# STM32H7B3x register map
File version: 2.2
CPU: CM7 r0p1, little endian, MPU, FPU, 4 interrupt priority bits
Registers are 32-bit, read-write, reset 0x0 unless marked. A register's access mark holds for its fields unless they carry their own. Offsets are from the block's base; [hi:lo] are bit positions.

## RNG
Base 0x48021800
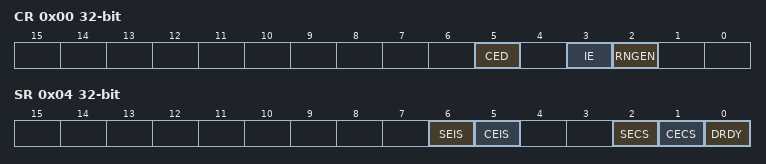
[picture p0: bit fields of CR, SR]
0x00 CR — RNG control register
  [5] CED — Clock error detection Note: The clock error detection can be used only when ck_rc48 or ck_pll1_q (ck_pll1_q = 48MHz) source is selected otherwise, CED bit must be equal to 1. The clock error detection cannot be enabled nor disabled on the fly when RNG peripheral is enabled, to enable or disable CED the RNG must be disabled.
    0=Enabled (Clock error detection is enabled); 1=Disabled (Clock error detection is disabled)
  [3] IE — Interrupt enable
    0=Disabled (RNG interrupt is disabled); 1=Enabled (RNG interrupt is enabled)
  [2] RNGEN — Random number generator enable
    0=Disabled (Random number generator is disabled); 1=Enabled (Random number generator is enabled)
0x04 SR access per field — RNG status register
  [6] SEIS rw — Seed error interrupt status This bit is set at the same time as SECS. It is cleared by writing it to 0. ** More than 64 consecutive bits at the same value (0 or 1) ** More than 32 consecutive alternances of 0 and 1 (0101010101...01) An interrupt is pending if IE = 1 in the RNG_CR register.
  [5] CEIS rw — Clock error interrupt status This bit is set at the same time as CECS. It is cleared by writing it to 0. An interrupt is pending if IE = 1 in the RNG_CR register. Note: This bit is meaningless if CED (Clock error detection) bit in RNG_CR is equal to 1.
  [2] SECS ro — Seed error current status ** More than 64 consecutive bits at the same value (0 or 1) ** More than 32 consecutive alternances of 0 and 1 (0101010101...01)
  [1] CECS ro — Clock error current status Note: This bit is meaningless if CED (Clock error detection) bit in RNG_CR is equal to 1.
  [0] DRDY ro — Data ready Note: If IE=1 in RNG_CR, an interrupt is generated when DRDY=1. It can rise when the peripheral is disabled. When the output buffer becomes empty (after reading RNG_DR), this bit returns to 0 until a new random value is generated.
0x08 DR ro — The RNG_DR register is a read-only register that delivers a 32-bit random value when read. The content of this register is valid when DRDY= 1, even if RNGEN=0.
  [31:0] RNDATA — Random data 32-bit random data which are valid when DRDY=1.

## SCB_ACTRL — System control block ACTLR
Base 0xE000E008
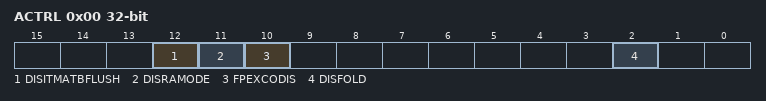
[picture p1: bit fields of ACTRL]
0x00 ACTRL — Auxiliary control register
  [12] DISITMATBFLUSH, [11] DISRAMODE, [10] FPEXCODIS, [2] DISFOLD

## SPDIFRX — Receiver Interface
Base 0x40004000
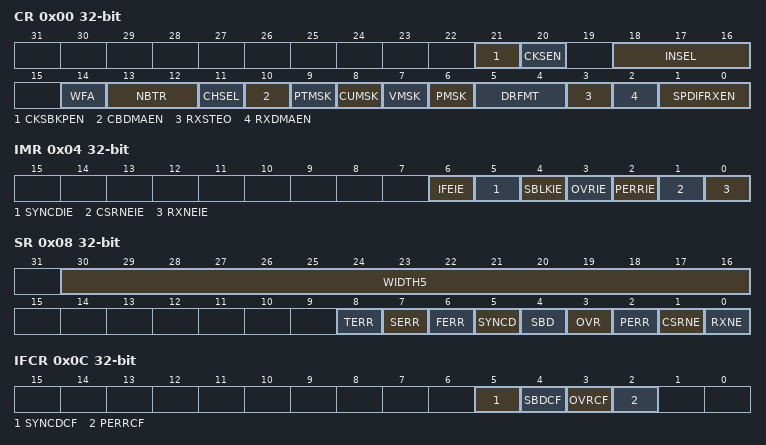
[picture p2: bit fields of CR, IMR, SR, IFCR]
0x00 CR — Control register
  [21] CKSBKPEN — Backup Symbol Clock Enable
  [20] CKSEN — Symbol Clock Enable
  [18:16] INSEL — input selection
  [14] WFA — Wait For Activity
  [13:12] NBTR — Maximum allowed re-tries during synchronization phase
  [11] CHSEL — Channel Selection
  [10] CBDMAEN — Control Buffer DMA ENable for control flow
  [9] PTMSK — Mask of Preamble Type bits
  [8] CUMSK — Mask of channel status and user bits
  [7] VMSK — Mask of Validity bit
  [6] PMSK — Mask Parity error bit
  [5:4] DRFMT — RX Data format
  [3] RXSTEO — STerEO Mode
  [2] RXDMAEN — Receiver DMA ENable for data flow
  [1:0] SPDIFRXEN — Peripheral Block Enable
0x04 IMR — Interrupt mask register
  [6] IFEIE — Serial Interface Error Interrupt Enable
  [5] SYNCDIE — Synchronization Done
  [4] SBLKIE — Synchronization Block Detected Interrupt Enable
  [3] OVRIE — Overrun error Interrupt Enable
  [2] PERRIE — Parity error interrupt enable
  [1] CSRNEIE — Control Buffer Ready Interrupt Enable
  [0] RXNEIE — RXNE interrupt enable
0x08 SR ro — Status register
  [30:16] WIDTH5 — Duration of 5 symbols counted with SPDIF_CLK
  [8] TERR — Time-out error
  [7] SERR — Synchronization error
  [6] FERR — Framing error
  [5] SYNCD — Synchronization Done
  [4] SBD — Synchronization Block Detected
  [3] OVR — Overrun error
  [2] PERR — Parity error
  [1] CSRNE — Control Buffer register is not empty
  [0] RXNE — Read data register not empty
0x0C IFCR wo — Interrupt Flag Clear register
  [5] SYNCDCF — Clears the Synchronization Done flag
  [4] SBDCF — Clears the Synchronization Block Detected flag
  [3] OVRCF — Clears the Overrun error flag
  [2] PERRCF — Clears the Parity error flag
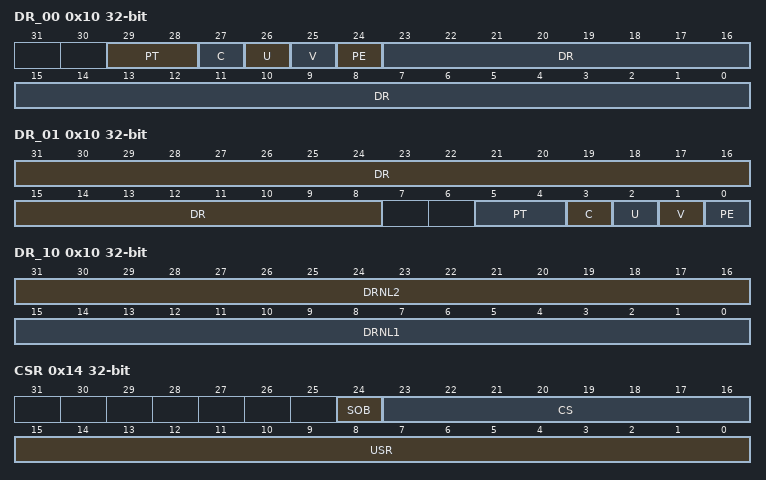
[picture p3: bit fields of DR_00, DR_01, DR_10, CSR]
0x10 DR_00 ro — Data input register
  [29:28] PT — Preamble Type
  [27] C — Channel Status bit
  [26] U — User bit
  [25] V — Validity bit
  [24] PE — Parity Error bit
  [23:0] DR — Parity Error bit
0x10 DR_01 ro (alternate view of DR_00) — Data input register
  [31:8] DR — Data value
  [5:4] PT — Preamble Type
  [3] C — Channel Status bit
  [2] U — User bit
  [1] V — Validity bit
  [0] PE — Parity Error bit
0x10 DR_10 ro — Data input register
  [31:16] DRNL2 — Data value
  [15:0] DRNL1 — Data value
0x14 CSR ro — Channel Status register
  [24] SOB — Start Of Block
  [23:16] CS — Channel A status information
  [15:0] USR — User data information
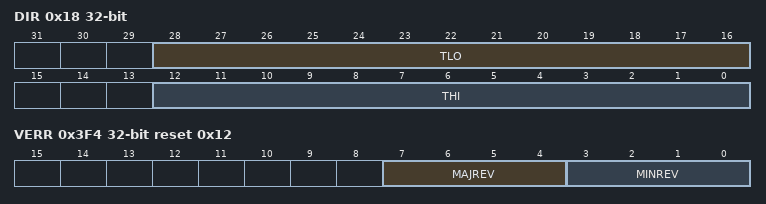
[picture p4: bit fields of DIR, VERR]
0x18 DIR ro — Debug Information register
  [28:16] TLO — Threshold LOW
  [12:0] THI — Threshold HIGH
0x3F4 VERR ro reset 0x12 — SPDIFRX version register
  [7:4] MAJREV — Major revision
  [3:0] MINREV — Minor revision
0x3F8 IDR ro reset 0x130041 — SPDIFRX identification register
  [31:0] ID — SPDIFRX identifier
0x3FC SIDR ro reset 0xA3C5DD01 — SPDIFRX size identification register
  [31:0] SID — Size identification
